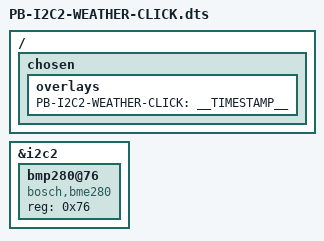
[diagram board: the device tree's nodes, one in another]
/*
 * Copyright (C) 2017 Robert Nelson <robertcnelson@gmail.com>
 *
 * This program is free software; you can redistribute it and/or modify
 * it under the terms of the GNU General Public License version 2 as
 * published by the Free Software Foundation.
 */
/dts-v1/;
/plugin/;

#include <dt-bindings/board/am335x-bbw-bbb-base.h>
#include <dt-bindings/gpio/gpio.h>
#include <dt-bindings/pinctrl/am33xx.h>

/ {
	/*
	 * Helper to show loaded overlays under: /proc/device-tree/chosen/overlays/
	 */
	fragment@0 {
		target-path="/";
		__overlay__ {

			chosen {
				overlays {
					PB-I2C2-WEATHER-CLICK = __TIMESTAMP__;
				};
			};
		};
	};

	fragment@1 {
		target = <&i2c2>;
		__overlay__ {
			status = "okay";

			#address-cells = <1>;
			#size-cells = <0>;

			bmp280@76 {
				compatible = "bosch,bme280";
				reg = <0x76>;
			};
		};
	};
};

